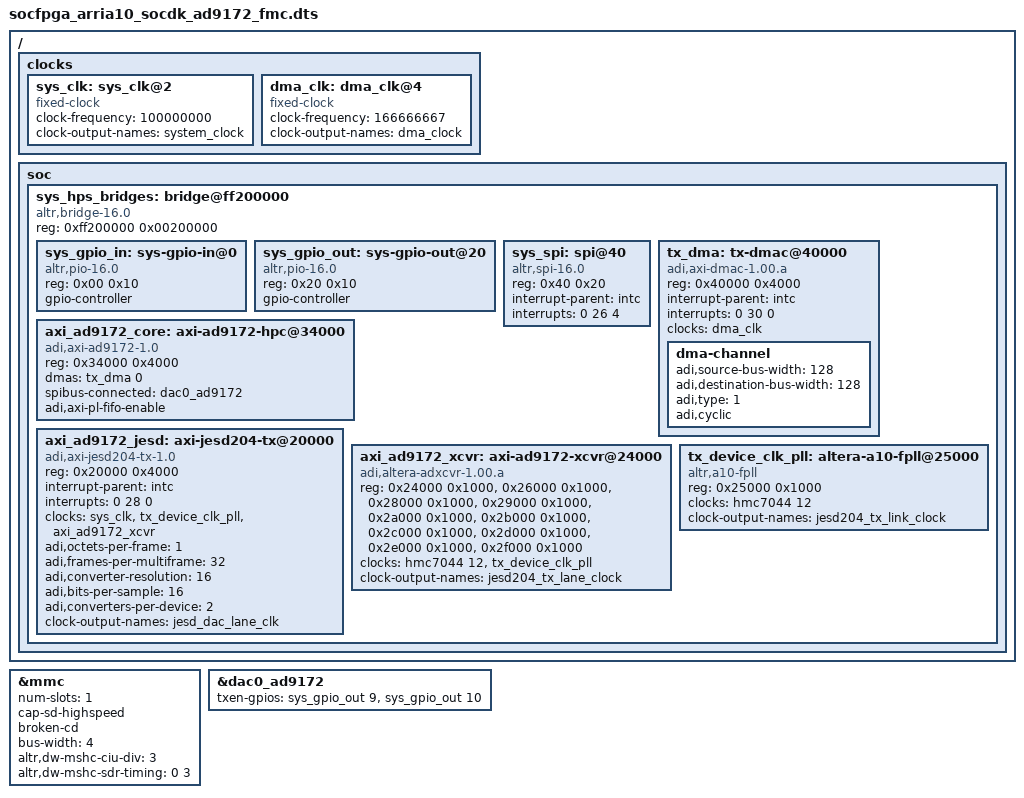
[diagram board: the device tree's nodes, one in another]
/dts-v1/;
#include "socfpga_arria10_socdk.dtsi"

&mmc {
	status = "okay";
	num-slots = <1>;
	cap-sd-highspeed;
	broken-cd;
	bus-width = <4>;
	altr,dw-mshc-ciu-div = <3>;
	altr,dw-mshc-sdr-timing = <0 3>;
};

/ {
	clocks {
		sys_clk: sys_clk@2 {
			#clock-cells = <0>;
			compatible = "fixed-clock";
			clock-frequency = <100000000>;
			clock-output-names = "system_clock";
		};

		dma_clk: dma_clk@4 {
			#clock-cells = <0>;
			compatible = "fixed-clock";
			clock-frequency = <166666667>;
			clock-output-names = "dma_clock";
		};
	};

	soc {
		sys_hps_bridges: bridge@ff200000 {
			compatible = "altr,bridge-16.0", "simple-bus";
			reg = <0xff200000 0x00200000>;
			#address-cells = <1>;
			#size-cells = <1>;
			ranges = <0x00000000 0xff200000 0x00200000>;

			sys_gpio_in: sys-gpio-in@0 {
				compatible = "altr,pio-16.0", "altr,pio-1.0";
				reg = <0x00 0x10>;
				#gpio-cells = <2>;
				gpio-controller;
			};

			sys_gpio_out: sys-gpio-out@20 {
				compatible = "altr,pio-16.0", "altr,pio-1.0";
				reg = <0x20 0x10>;
				#gpio-cells = <2>;
				gpio-controller;
			};

			sys_spi: spi@40 {
				compatible = "altr,spi-16.0", "altr,spi-1.0";
				reg = <0x40 0x20>;
				interrupt-parent = <&intc>;
				interrupts = <0 26 4>;
				#address-cells = <0x1>;
				#size-cells = <0x0>;
			};

			tx_dma: tx-dmac@40000 {
				compatible = "adi,axi-dmac-1.00.a";
				reg = <0x40000 0x4000>;
				#dma-cells = <1>;
				interrupt-parent = <&intc>;
				interrupts = <0 30 0>;
				clocks = <&dma_clk>;

				dma-channel {
					adi,source-bus-width = <128>;
					adi,destination-bus-width = <128>;
					adi,type = <1>;
					adi,cyclic;
				};
			};

			axi_ad9172_core: axi-ad9172-hpc@34000 {
				compatible = "adi,axi-ad9172-1.0";
				reg = <0x34000 0x4000>;
				dmas = <&tx_dma 0>;
				dma-names = "tx";
				spibus-connected = <&dac0_ad9172>;
				adi,axi-pl-fifo-enable;
			};

			axi_ad9172_jesd: axi-jesd204-tx@20000 {
				compatible = "adi,axi-jesd204-tx-1.0";
				reg = <0x20000 0x4000>;

				interrupt-parent = <&intc>;
				interrupts = <0 28 0>;

				clocks = <&sys_clk>, <&tx_device_clk_pll>, <&axi_ad9172_xcvr>;
				clock-names = "s_axi_aclk", "device_clk", "lane_clk";

				adi,octets-per-frame = <1>;
				adi,frames-per-multiframe = <32>;
				adi,converter-resolution = <16>;
				adi,bits-per-sample = <16>;
				adi,converters-per-device = <2>;

				#clock-cells = <0>;
				clock-output-names = "jesd_dac_lane_clk";
			};

			axi_ad9172_xcvr: axi-ad9172-xcvr@24000 {
				compatible = "adi,altera-adxcvr-1.00.a";
				reg = <0x24000 0x1000>,
				      <0x26000 0x1000>,
				      <0x28000 0x1000>,
				      <0x29000 0x1000>,
				      <0x2a000 0x1000>,
				      <0x2b000 0x1000>,
				      <0x2c000 0x1000>,
				      <0x2d000 0x1000>,
				      <0x2e000 0x1000>,
				      <0x2f000 0x1000>;
				reg-names = "adxcvr", "atx-pll",
					"adxcfg-0", "adxcfg-1", "adxcfg-2", "adxcfg-3",
					"adxcfg-4", "adxcfg-5", "adxcfg-6", "adxcfg-7";

				#clock-cells = <0>;
				clocks = <&hmc7044 12>, <&tx_device_clk_pll>;
				clock-names = "ref", "link";
				clock-output-names = "jesd204_tx_lane_clock";
			};

			tx_device_clk_pll: altera-a10-fpll@25000 {
				compatible = "altr,a10-fpll";
				reg = <0x25000 0x1000>;
				#clock-cells = <0>;
				clocks = <&hmc7044 12>;
				clock-output-names = "jesd204_tx_link_clock";
			};
		};
	};
};

#define fmc_spi sys_spi

#include "adi-ad9172-fmc-ebz.dtsi"

&dac0_ad9172 {
	txen-gpios = <&sys_gpio_out 9 0>, <&sys_gpio_out 10 0>;
};
